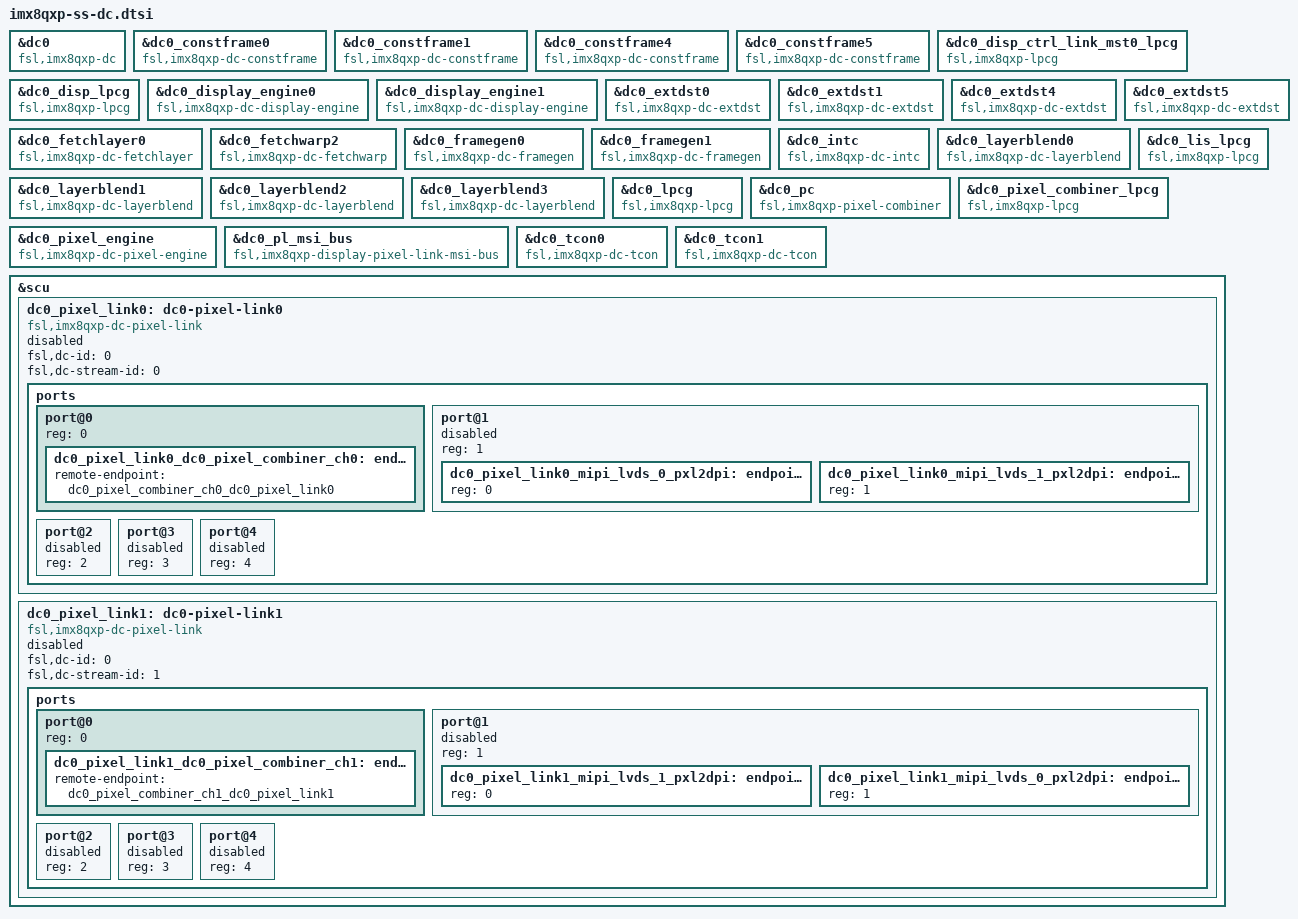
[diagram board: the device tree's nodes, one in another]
// SPDX-License-Identifier: GPL-2.0+
/*
 * Copyright 2024 NXP
 */

&dc0 {
	compatible = "fsl,imx8qxp-dc";
};

&dc0_constframe0 {
	compatible = "fsl,imx8qxp-dc-constframe";
};

&dc0_constframe1 {
	compatible = "fsl,imx8qxp-dc-constframe";
};

&dc0_constframe4 {
	compatible = "fsl,imx8qxp-dc-constframe";
};

&dc0_constframe5 {
	compatible = "fsl,imx8qxp-dc-constframe";
};

&dc0_disp_ctrl_link_mst0_lpcg {
	compatible = "fsl,imx8qxp-lpcg";
};

&dc0_disp_lpcg {
	compatible = "fsl,imx8qxp-lpcg";
};

&dc0_display_engine0 {
	compatible = "fsl,imx8qxp-dc-display-engine";
};

&dc0_display_engine1 {
	compatible = "fsl,imx8qxp-dc-display-engine";
};

&dc0_extdst0 {
	compatible = "fsl,imx8qxp-dc-extdst";
};

&dc0_extdst1 {
	compatible = "fsl,imx8qxp-dc-extdst";
};

&dc0_extdst4 {
	compatible = "fsl,imx8qxp-dc-extdst";
};

&dc0_extdst5 {
	compatible = "fsl,imx8qxp-dc-extdst";
};

&dc0_fetchlayer0 {
	compatible = "fsl,imx8qxp-dc-fetchlayer";
};

&dc0_fetchwarp2 {
	compatible = "fsl,imx8qxp-dc-fetchwarp";
};

&dc0_framegen0 {
	compatible = "fsl,imx8qxp-dc-framegen";
};

&dc0_framegen1 {
	compatible = "fsl,imx8qxp-dc-framegen";
};

&dc0_intc {
	compatible = "fsl,imx8qxp-dc-intc";
};

&dc0_layerblend0 {
	compatible = "fsl,imx8qxp-dc-layerblend";
};

&dc0_layerblend1 {
	compatible = "fsl,imx8qxp-dc-layerblend";
};

&dc0_layerblend2 {
	compatible = "fsl,imx8qxp-dc-layerblend";
};

&dc0_layerblend3 {
	compatible = "fsl,imx8qxp-dc-layerblend";
};

&dc0_lis_lpcg {
	compatible = "fsl,imx8qxp-lpcg";
};

&dc0_lpcg {
	compatible = "fsl,imx8qxp-lpcg";
};

&dc0_pc {
	compatible = "fsl,imx8qxp-pixel-combiner";
};

&dc0_pixel_combiner_lpcg {
	compatible = "fsl,imx8qxp-lpcg";
};

&dc0_pixel_engine {
	compatible = "fsl,imx8qxp-dc-pixel-engine";
};

&dc0_pl_msi_bus {
	compatible = "fsl,imx8qxp-display-pixel-link-msi-bus", "simple-pm-bus";
};

&dc0_tcon0 {
	compatible = "fsl,imx8qxp-dc-tcon";
};

&dc0_tcon1 {
	compatible = "fsl,imx8qxp-dc-tcon";
};

&scu {
	dc0_pixel_link0: dc0-pixel-link0 {
		compatible = "fsl,imx8qxp-dc-pixel-link";
		fsl,dc-id = /bits/ 8 <0>;
		fsl,dc-stream-id = /bits/ 8 <0>;
		status = "disabled";

		ports {
			#address-cells = <1>;
			#size-cells = <0>;

			/* from dc0 pixel combiner channel0 */
			port@0 {
				reg = <0>;

				dc0_pixel_link0_dc0_pixel_combiner_ch0: endpoint {
					remote-endpoint = <&dc0_pixel_combiner_ch0_dc0_pixel_link0>;
				};
			};

			/* to PXL2DPIs in MIPI/LVDS combo subsystems */
			port@1 {
				#address-cells = <1>;
				#size-cells = <0>;
				reg = <1>;
				status = "disabled";

				dc0_pixel_link0_mipi_lvds_0_pxl2dpi: endpoint@0 {
					reg = <0>;
				};

				dc0_pixel_link0_mipi_lvds_1_pxl2dpi: endpoint@1 {
					reg = <1>;
				};
			};

			/* unused */
			port@2 {
				reg = <2>;
				status = "disabled";
			};

			/* unused */
			port@3 {
				reg = <3>;
				status = "disabled";
			};

			/* to imaging subsystem */
			port@4 {
				reg = <4>;
				status = "disabled";
			};
		};
	};

	dc0_pixel_link1: dc0-pixel-link1 {
		compatible = "fsl,imx8qxp-dc-pixel-link";
		fsl,dc-id = /bits/ 8 <0>;
		fsl,dc-stream-id = /bits/ 8 <1>;
		status = "disabled";

		ports {
			#address-cells = <1>;
			#size-cells = <0>;

			/* from dc0 pixel combiner channel1 */
			port@0 {
				reg = <0>;

				dc0_pixel_link1_dc0_pixel_combiner_ch1: endpoint {
					remote-endpoint = <&dc0_pixel_combiner_ch1_dc0_pixel_link1>;
				};
			};

			/* to PXL2DPIs in MIPI/LVDS combo subsystems */
			port@1 {
				#address-cells = <1>;
				#size-cells = <0>;
				reg = <1>;
				status = "disabled";

				dc0_pixel_link1_mipi_lvds_1_pxl2dpi: endpoint@0 {
					reg = <0>;
				};

				dc0_pixel_link1_mipi_lvds_0_pxl2dpi: endpoint@1 {
					reg = <1>;
				};
			};

			/* to parallel display interface in ADMA subsystem */
			port@2 {
				reg = <2>;
				status = "disabled";
			};

			/* unused */
			port@3 {
				reg = <3>;
				status = "disabled";
			};

			/* unused */
			port@4 {
				reg = <4>;
				status = "disabled";
			};
		};
	};
};
